# Qorvo_SVD register map
Vendor: Qorvo Inc; Series: ARMCM4; File version: 1.0
Registers are 8-bit, read-write, reset 0x0 unless marked. A register's access mark holds for its fields unless they carry their own. Offsets are from the block's base; [hi:lo] are bit positions; {n}, {i} and the like mark numbered series.

## ES
Base 0x40000900
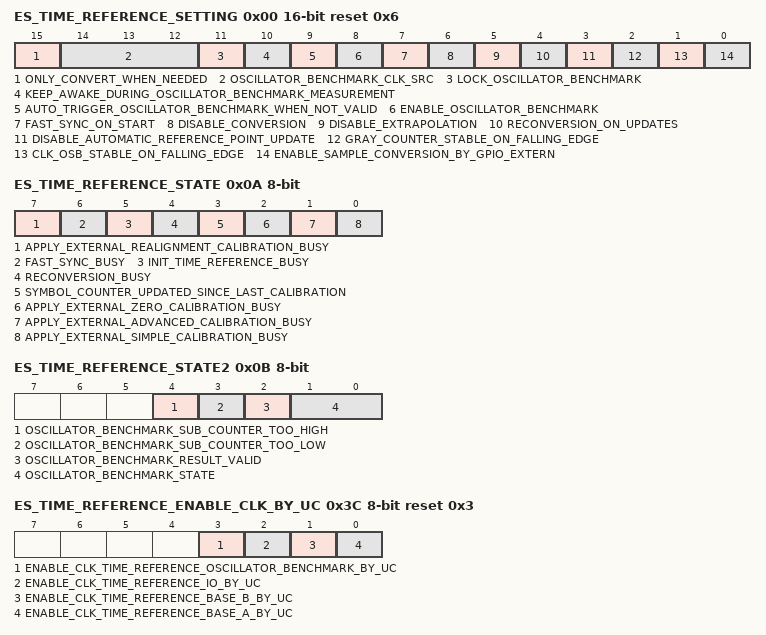
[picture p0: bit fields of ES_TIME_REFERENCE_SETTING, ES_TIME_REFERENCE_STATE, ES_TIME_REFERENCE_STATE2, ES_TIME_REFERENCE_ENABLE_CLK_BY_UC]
0x00 ES_TIME_REFERENCE_SETTING 16-bit reset 0x6
  [15] ONLY_CONVERT_WHEN_NEEDED — only convert when needed, automatically disabling the conversion, only enable when symbol counter is not initialized or when a calibration (e.g. realignment) is to be executed
  [14:12] OSCILLATOR_BENCHMARK_CLK_SRC — determines what clock to use for the oscillator benchmark test
  [11] LOCK_OSCILLATOR_BENCHMARK
  [10] KEEP_AWAKE_DURING_OSCILLATOR_BENCHMARK_MEASUREMENT
  [9] AUTO_TRIGGER_OSCILLATOR_BENCHMARK_WHEN_NOT_VALID — Auto trigger oscillator benchmark when oscillator benchmark is not valid
  [8] ENABLE_OSCILLATOR_BENCHMARK
  [7] FAST_SYNC_ON_START
  [6] DISABLE_CONVERSION
  [5] DISABLE_EXTRAPOLATION
  [4] RECONVERSION_ON_UPDATES
  [3] DISABLE_AUTOMATIC_REFERENCE_POINT_UPDATE
  [2] GRAY_COUNTER_STABLE_ON_FALLING_EDGE — Select on which edge of standby clock the gray counter is stable
  [1] CLK_OSB_STABLE_ON_FALLING_EDGE — Select what edge of oscillator benchmark clk is jitter free
  [0] ENABLE_SAMPLE_CONVERSION_BY_GPIO_EXTERN
0x02 ES_0X00000002 16-bit
  [11:0] OSCILLATOR_BENCHMARK_LP_TICKS_THRESHOLD — The number of ticks (+1) of the low power oscillator that is used by the oscillator benchmark to measure the number of 32MHz ticks over
0x04 ES_0X00000004 16-bit
  [11:0] OSCILLATOR_BENCHMARK_SUB_COUNTER_MIN — The minimum number of oscillator ticks expected during a 1 slow clock period
0x06 ES_0X00000006 16-bit
  [11:0] OSCILLATOR_BENCHMARK_SUB_COUNTER_MAX — The maximum number of oscillator ticks expected during a 1 slow clock period
0x0A ES_TIME_REFERENCE_STATE ro
  [7] APPLY_EXTERNAL_REALIGNMENT_CALIBRATION_BUSY — Apply Realignment Calibration Bus
  [6] FAST_SYNC_BUSY
  [5] INIT_TIME_REFERENCE_BUSY — Init Event Scheduler Busy
  [4] RECONVERSION_BUSY
  [3] SYMBOL_COUNTER_UPDATED_SINCE_LAST_CALIBRATION
  [2] APPLY_EXTERNAL_ZERO_CALIBRATION_BUSY — Apply Zero Calibration Busy
  [1] APPLY_EXTERNAL_ADVANCED_CALIBRATION_BUSY — Apply Advanced Calibration Busy
  [0] APPLY_EXTERNAL_SIMPLE_CALIBRATION_BUSY — Apply Simple Calibration Busy
0x0B ES_TIME_REFERENCE_STATE2 ro
  [4] OSCILLATOR_BENCHMARK_SUB_COUNTER_TOO_HIGH — status indicationg that during a measurement period, the number of ticks for 1 slow period was above the allowed max value
  [3] OSCILLATOR_BENCHMARK_SUB_COUNTER_TOO_LOW — status indicationg that during a measurement period, the number of ticks for 1 slow period was below the allowed min value
  [2] OSCILLATOR_BENCHMARK_RESULT_VALID
  [1:0] OSCILLATOR_BENCHMARK_STATE
0x0C ES_0X0000000C 32-bit ro
  [31:0] AUTO_SAMPLED_SYMBOL_COUNTER — Auto Sample Symbol Counter
0x10 ES_0X00000010 32-bit ro
  [31:0] AUTO_SAMPLED_SYMBOL_COUNTER_ALTERNATE — Second auto samppled symbol counter, dedicated for second processor in the sybsystem
0x14 ES_0X00000014 32-bit
  [31:0] BINARY_GRAY_COUNTER
0x18 ES_0X00000018 32-bit
  [31:0] SYMBOL_COUNTER
{0x1C+i} ES_0X0000001C[{i}] ro (i=0..2)
  [7:0] OSCILLATOR_BENCHMARK_COUNTER[{i}] — Number of 32MHz ticks seen by the oscillator benchmark
0x20 ES_0X00000020 16-bit ro
  [15:0] OSCILLATOR_BENCHMARK_LP_TICKS_SEEN — Number of low power oscillator ticks seen by the oscillator benchmark
0x22 ES_0X00000022 16-bit ro
  [11:0] OSCILLATOR_BENCHMARK_SUB_COUNTER_RESULT — Number of low power oscillator ticks seen by the oscillator during 1 tick of the slow clock
0x24 ES_0X00000024 32-bit reset 0x1000
  [31:0] STARTUP_SYMBOL_TIME — Startup symbol time. Resolution is 1 us
0x28 ES_0X00000028 32-bit reset 0x2000
  [31:0] LONG_STARTUP_SYMBOL_TIME — Startup long symbol time. Resolution is 1 us
0x2C ES_0X0000002C 32-bit
  [31:0] BINARY_GRAY_COUNTER_REFERENCE
0x30 ES_0X00000030 32-bit
  [31:0] SYMBOL_COUNTER_REFERENCE
0x34 ES_0X00000034 32-bit reset 0x40000000
  [31:0] CALIBRATION_FACTOR
0x38 ES_0X00000038 32-bit
  [31:0] PHASE_COMPENSATION
0x3C ES_TIME_REFERENCE_ENABLE_CLK_BY_UC reset 0x3
  [3] ENABLE_CLK_TIME_REFERENCE_OSCILLATOR_BENCHMARK_BY_UC, [2] ENABLE_CLK_TIME_REFERENCE_IO_BY_UC, [1] ENABLE_CLK_TIME_REFERENCE_BASE_B_BY_UC, [0] ENABLE_CLK_TIME_REFERENCE_BASE_A_BY_UC
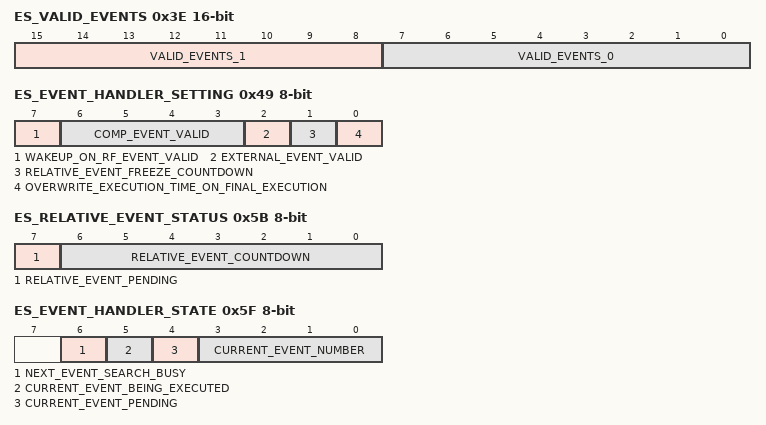
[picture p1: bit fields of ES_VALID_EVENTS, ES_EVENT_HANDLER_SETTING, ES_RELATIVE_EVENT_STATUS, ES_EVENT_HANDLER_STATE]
0x3E ES_VALID_EVENTS 16-bit ro
  [15:8] VALID_EVENTS_1 — Valid Events
  [7:0] VALID_EVENTS_0 — Valid Events
0x44 ES_0X00000044 16-bit reset 0x1
  [15:0] BUFFER_TIME
0x46 ES_0X00000046 16-bit
  [15:0] PRIORITY_TIME — Priotiry time
0x48 ES_0X00000048 reset 0x1F
  [4:0] GUARD_TIME_SEL — Guard Time Selector
0x49 ES_EVENT_HANDLER_SETTING
  [7] WAKEUP_ON_RF_EVENT_VALID
  [6:3] COMP_EVENT_VALID — Comparator event valid
  [2] EXTERNAL_EVENT_VALID
  [1] RELATIVE_EVENT_FREEZE_COUNTDOWN — Freeze relative event countdown
  [0] OVERWRITE_EXECUTION_TIME_ON_FINAL_EXECUTION
0x4A ES_0X0000004A
  [7:0] EXTERNAL_EVENT_TYPE_TO_BE_EXECUTED — External event type
0x4C ES_0X0000004C 16-bit
  [15:0] EXTERNAL_EVENT_CUSTOM_DATA — Custom data of external event
0x4F ES_0X0000004F
  [7:0] RELATIVE_EVENT_TYPE_TO_BE_EXECUTED — Relative event type
0x50 ES_0X00000050 16-bit
  [15:0] RELATIVE_EVENT_CUSTOM_DATA — Custom data of relative event
0x52 ES_0X00000052
  [7:0] COMP_EVENT_TYPE_TO_BE_EXECUTED — Comparator event type
0x54 ES_0X00000054 16-bit
  [15:0] COMP_EVENT_CUSTOM_DATA — Custom data of comparator event
0x56 ES_0X00000056
  [7:0] WAKEUP_ON_RF_EVENT_TYPE_TO_BE_EXECUTED — Wakeup_on_rf event type
0x58 ES_0X00000058 16-bit
  [15:0] WAKEUP_ON_RF_EVENT_CUSTOM_DATA — Custom data of wakeup_on_rf event
0x5A ES_0X0000005A
  [6:0] RELATIVE_EVENT_TIME_DELAY — Time delay (in multiples of 16 us) after which the event wil be executed
0x5B ES_RELATIVE_EVENT_STATUS ro
  [7] RELATIVE_EVENT_PENDING, [6:0] RELATIVE_EVENT_COUNTDOWN
0x5C ES_0X0000005C 16-bit reset 0xFF
  [15:0] DITHER_SEED
0x5E ES_0X0000005E reset 0x7
  [7:0] DITHER_BACKOFF_EXPONENT_MASK
0x5F ES_EVENT_HANDLER_STATE ro
  [6] NEXT_EVENT_SEARCH_BUSY, [5] CURRENT_EVENT_BEING_EXECUTED, [4] CURRENT_EVENT_PENDING, [3:0] CURRENT_EVENT_NUMBER
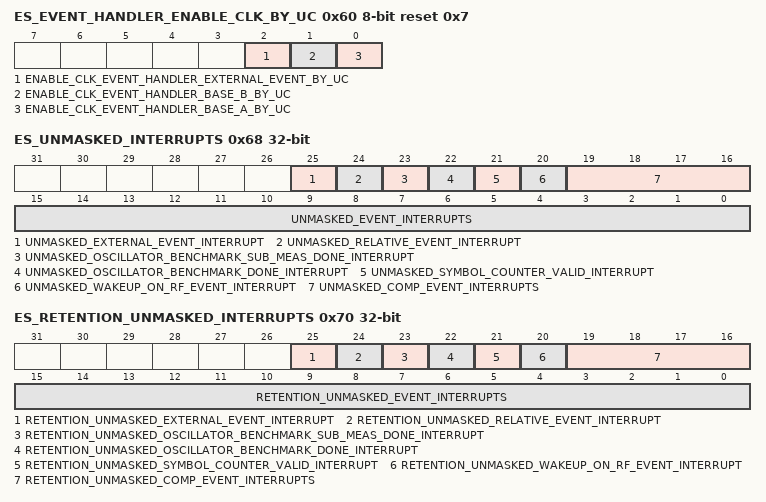
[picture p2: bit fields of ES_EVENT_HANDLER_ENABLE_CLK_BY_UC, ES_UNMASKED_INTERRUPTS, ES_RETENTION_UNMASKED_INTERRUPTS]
0x60 ES_EVENT_HANDLER_ENABLE_CLK_BY_UC reset 0x7
  [2] ENABLE_CLK_EVENT_HANDLER_EXTERNAL_EVENT_BY_UC, [1] ENABLE_CLK_EVENT_HANDLER_BASE_B_BY_UC, [0] ENABLE_CLK_EVENT_HANDLER_BASE_A_BY_UC
0x64 ES_LAST_EXTERNAL_PIN_EVENT_STATE[0] ro
  [7:0] LAST_EXTERNAL_PIN_EVENT_STATE[0] — event state of the external pins when last external pin event occurred
0x65 ES_LAST_EXTERNAL_PIN_EVENT_STATE[1] ro
  [7:0] LAST_EXTERNAL_PIN_EVENT_STATE[1] — event state of the external pins when last external pin event occurred
0x66 ES_LAST_EXTERNAL_PIN_EVENT_STATE[2] ro
  [6:0] LAST_EXTERNAL_PIN_EVENT_STATE[2] — event state of the external pins when last external pin event occurred
0x68 ES_UNMASKED_INTERRUPTS 32-bit ro
  [25] UNMASKED_EXTERNAL_EVENT_INTERRUPT
  [24] UNMASKED_RELATIVE_EVENT_INTERRUPT
  [23] UNMASKED_OSCILLATOR_BENCHMARK_SUB_MEAS_DONE_INTERRUPT — Unmasked Oscillator Benchmark Done Interrupt
  [22] UNMASKED_OSCILLATOR_BENCHMARK_DONE_INTERRUPT
  [21] UNMASKED_SYMBOL_COUNTER_VALID_INTERRUPT
  [20] UNMASKED_WAKEUP_ON_RF_EVENT_INTERRUPT — Unmasked wakeup_on_rf event interrupts
  [19:16] UNMASKED_COMP_EVENT_INTERRUPTS — Unmasked comparator event interrupts
  [15:0] UNMASKED_EVENT_INTERRUPTS
0x70 ES_RETENTION_UNMASKED_INTERRUPTS 32-bit
  [25] RETENTION_UNMASKED_EXTERNAL_EVENT_INTERRUPT
  [24] RETENTION_UNMASKED_RELATIVE_EVENT_INTERRUPT
  [23] RETENTION_UNMASKED_OSCILLATOR_BENCHMARK_SUB_MEAS_DONE_INTERRUPT — Unmasked Oscillator Benchmark sub measurement Done Interrupt
  [22] RETENTION_UNMASKED_OSCILLATOR_BENCHMARK_DONE_INTERRUPT — Unmasked Oscillator Benchmark Done Interrupt
  [21] RETENTION_UNMASKED_SYMBOL_COUNTER_VALID_INTERRUPT — Retention unmasked symbol counter interrupt
  [20] RETENTION_UNMASKED_WAKEUP_ON_RF_EVENT_INTERRUPT — Retention unmasked wakeup_on_rf Event Interrupts
  [19:16] RETENTION_UNMASKED_COMP_EVENT_INTERRUPTS
  [15:0] RETENTION_UNMASKED_EVENT_INTERRUPTS
0x74 ES_0X00000074 32-bit
  [31:0] CALIBRATION_FACTOR_ADJUSTMENT
